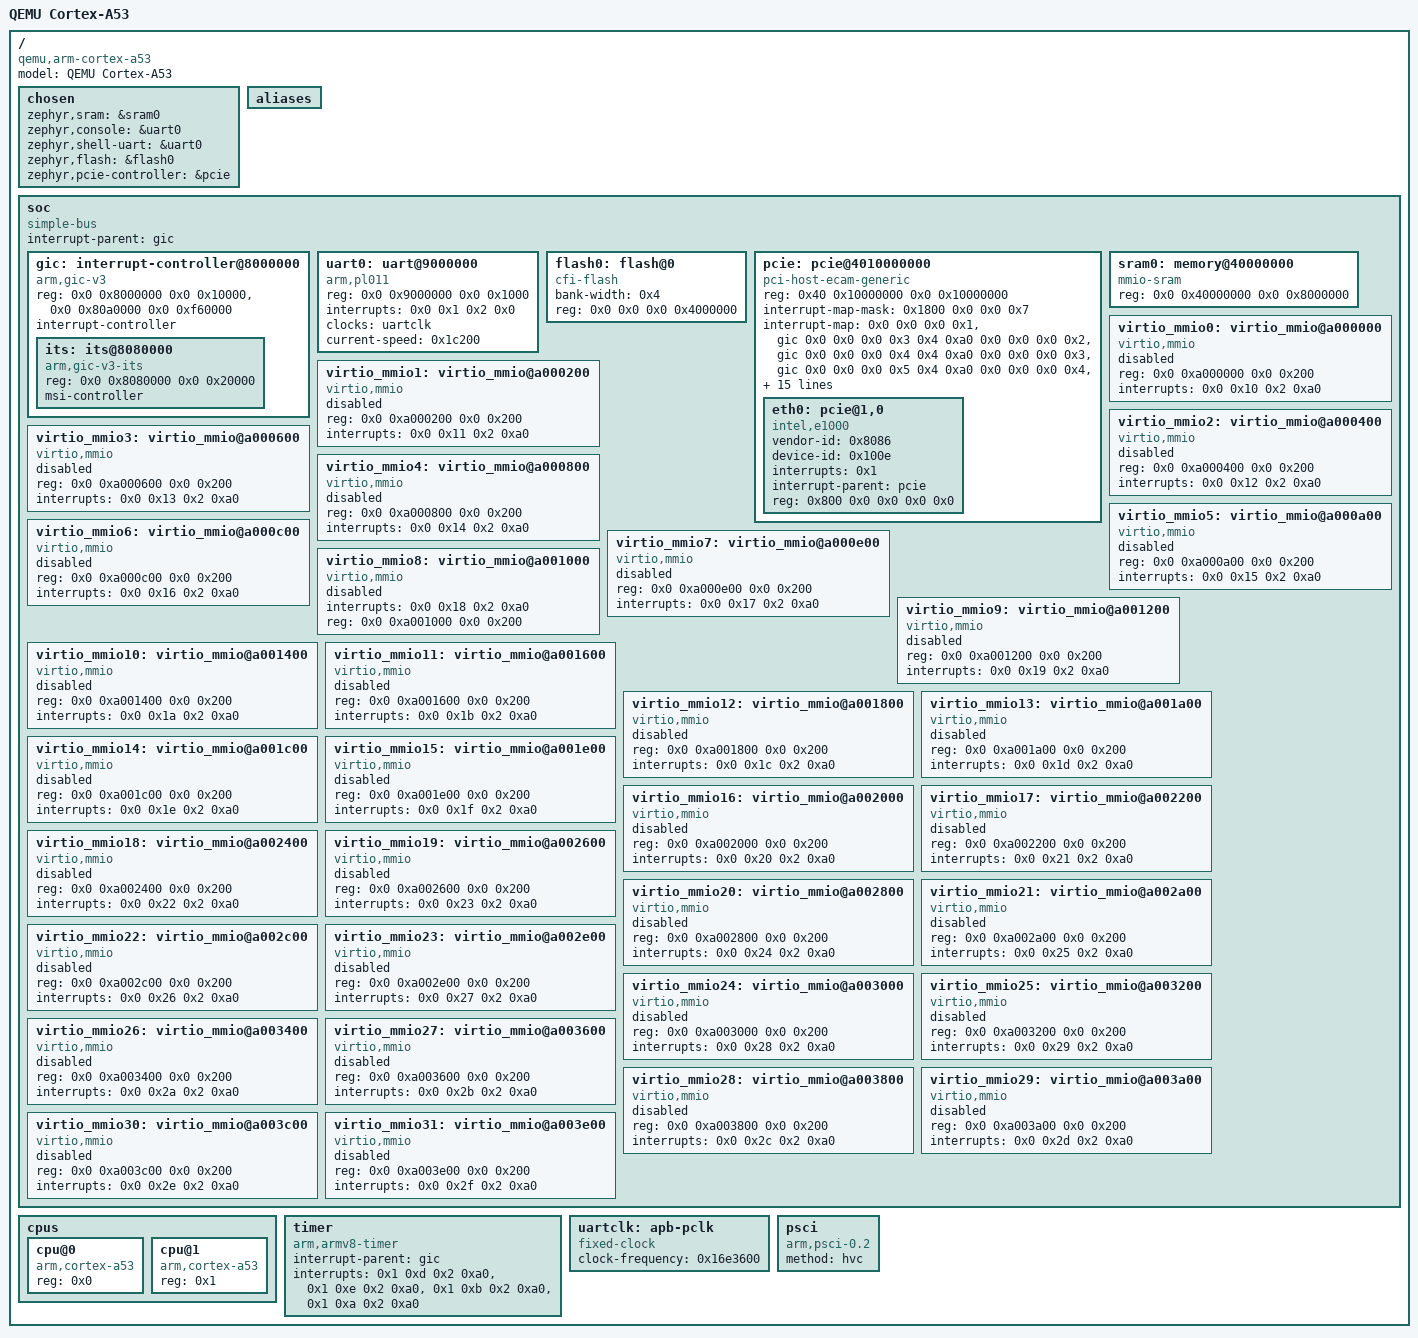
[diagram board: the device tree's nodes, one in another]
/dts-v1/;

/* node '/' defined in zephyr/dts/common/skeleton.dtsi:9 */
/ {
	#address-cells = < 0x2 >;           /* in zephyr/dts/arm64/qemu/qemu-virt-a53.dtsi:22 */
	#size-cells = < 0x2 >;              /* in zephyr/dts/arm64/qemu/qemu-virt-a53.dtsi:23 */
	model = "QEMU Cortex-A53";          /* in zephyr/boards/qemu/cortex_a53/qemu_cortex_a53.dts:12 */
	compatible = "qemu,arm-cortex-a53"; /* in zephyr/boards/qemu/cortex_a53/qemu_cortex_a53.dts:13 */

	/* node '/chosen' defined in zephyr/dts/common/skeleton.dtsi:13 */
	chosen {
		zephyr,sram = &sram0;           /* in zephyr/boards/qemu/cortex_a53/qemu_cortex_a53.dts:21 */
		zephyr,console = &uart0;        /* in zephyr/boards/qemu/cortex_a53/qemu_cortex_a53.dts:22 */
		zephyr,shell-uart = &uart0;     /* in zephyr/boards/qemu/cortex_a53/qemu_cortex_a53.dts:23 */
		zephyr,flash = &flash0;         /* in zephyr/boards/qemu/cortex_a53/qemu_cortex_a53.dts:24 */
		zephyr,pcie-controller = &pcie; /* in zephyr/boards/qemu/cortex_a53/qemu_cortex_a53.dts:25 */
	};

	/* node '/aliases' defined in zephyr/dts/common/skeleton.dtsi:15 */
	aliases {
	};

	/* node '/soc' defined in zephyr/dts/arm64/armv8-a.dtsi:10 */
	soc {
		compatible = "simple-bus";   /* in zephyr/dts/arm64/armv8-a.dtsi:13 */
		#address-cells = < 0x2 >;    /* in zephyr/dts/arm64/qemu/qemu-virt-a53.dtsi:62 */
		#size-cells = < 0x2 >;       /* in zephyr/dts/arm64/qemu/qemu-virt-a53.dtsi:63 */
		ranges;                      /* in zephyr/dts/arm64/qemu/qemu-virt-a53.dtsi:64 */
		interrupt-parent = < &gic >; /* in zephyr/dts/arm64/qemu/qemu-virt-a53.dtsi:66 */

		/* node '/soc/interrupt-controller@8000000' defined in zephyr/dts/arm64/qemu/qemu-virt-a53.dtsi:68 */
		gic: interrupt-controller@8000000 {
			compatible = "arm,gic-v3",
			             "arm,gic";               /* in zephyr/dts/arm64/qemu/qemu-virt-a53.dtsi:69 */
			reg = < 0x0 0x8000000 0x0 0x10000 >,
			      < 0x0 0x80a0000 0x0 0xf60000 >; /* in zephyr/dts/arm64/qemu/qemu-virt-a53.dtsi:70 */
			interrupt-controller;                 /* in zephyr/dts/arm64/qemu/qemu-virt-a53.dtsi:72 */
			#interrupt-cells = < 0x4 >;           /* in zephyr/dts/arm64/qemu/qemu-virt-a53.dtsi:73 */
			status = "okay";                      /* in zephyr/dts/arm64/qemu/qemu-virt-a53.dtsi:74 */
			#size-cells = < 0x2 >;                /* in zephyr/dts/arm64/qemu/qemu-virt-a53.dtsi:75 */
			#address-cells = < 0x2 >;             /* in zephyr/dts/arm64/qemu/qemu-virt-a53.dtsi:76 */
			phandle = < 0x1 >;                    /* in zephyr/dts/arm64/qemu/qemu-virt-a53.dtsi:66 */

			/* node '/soc/interrupt-controller@8000000/its@8080000' defined in zephyr/dts/arm64/qemu/qemu-virt-a53.dtsi:78 */
			its: its@8080000 {
				compatible = "arm,gic-v3-its";       /* in zephyr/dts/arm64/qemu/qemu-virt-a53.dtsi:79 */
				reg = < 0x0 0x8080000 0x0 0x20000 >; /* in zephyr/dts/arm64/qemu/qemu-virt-a53.dtsi:80 */
				msi-controller;                      /* in zephyr/dts/arm64/qemu/qemu-virt-a53.dtsi:81 */
				phandle = < 0x3 >;                   /* in zephyr/dts/arm64/qemu/qemu-virt-a53.dtsi:147 */
			};
		};

		/* node '/soc/uart@9000000' defined in zephyr/dts/arm64/qemu/qemu-virt-a53.dtsi:85 */
		uart0: uart@9000000 {
			compatible = "arm,pl011";           /* in zephyr/dts/arm64/qemu/qemu-virt-a53.dtsi:86 */
			reg = < 0x0 0x9000000 0x0 0x1000 >; /* in zephyr/dts/arm64/qemu/qemu-virt-a53.dtsi:87 */
			interrupts = < 0x0 0x1 0x2 0x0 >;   /* in zephyr/dts/arm64/qemu/qemu-virt-a53.dtsi:89 */
			interrupt-names = "irq_0";          /* in zephyr/dts/arm64/qemu/qemu-virt-a53.dtsi:90 */
			clocks = < &uartclk >;              /* in zephyr/dts/arm64/qemu/qemu-virt-a53.dtsi:91 */
			status = "okay";                    /* in zephyr/boards/qemu/cortex_a53/qemu_cortex_a53.dts:261 */
			current-speed = < 0x1c200 >;        /* in zephyr/boards/qemu/cortex_a53/qemu_cortex_a53.dts:262 */
		};

		/* node '/soc/flash@0' defined in zephyr/dts/arm64/qemu/qemu-virt-a53.dtsi:94 */
		flash0: flash@0 {
			compatible = "cfi-flash";        /* in zephyr/dts/arm64/qemu/qemu-virt-a53.dtsi:95 */
			bank-width = < 0x4 >;            /* in zephyr/dts/arm64/qemu/qemu-virt-a53.dtsi:96 */
			reg = < 0x0 0x0 0x0 0x4000000 >; /* in zephyr/dts/arm64/qemu/qemu-virt-a53.dtsi:101 */
		};

		/* node '/soc/pcie@4010000000' defined in zephyr/dts/arm64/qemu/qemu-virt-a53.dtsi:104 */
		pcie: pcie@4010000000 {
			compatible = "pci-host-ecam-generic";                                                                 /* in zephyr/dts/arm64/qemu/qemu-virt-a53.dtsi:105 */
			device_type = "pci";                                                                                  /* in zephyr/dts/arm64/qemu/qemu-virt-a53.dtsi:106 */
			reg = < 0x40 0x10000000 0x0 0x10000000 >;                                                             /* in zephyr/dts/arm64/qemu/qemu-virt-a53.dtsi:107 */
			#size-cells = < 0x2 >;                                                                                /* in zephyr/dts/arm64/qemu/qemu-virt-a53.dtsi:108 */
			#address-cells = < 0x3 >;                                                                             /* in zephyr/dts/arm64/qemu/qemu-virt-a53.dtsi:109 */
			ranges = < 0x1000000 0x0 0x0 0x0 0x3eff0000 0x0 0x10000 0x2000000 0x0 0x10000000 0x0 0x10000000
			           0x0 0x2eff0000 0x3000000 0x80 0x0 0x80 0x0 0x80 0x0 >;                                     /* in zephyr/dts/arm64/qemu/qemu-virt-a53.dtsi:110 */
			#interrupt-cells = < 0x1 >;                                                                           /* in zephyr/dts/arm64/qemu/qemu-virt-a53.dtsi:113 */
			interrupt-map-mask = < 0x1800 0x0 0x0 0x7 >;                                                          /* in zephyr/dts/arm64/qemu/qemu-virt-a53.dtsi:114 */
			interrupt-map = < 0x0 0x0 0x0 0x1 &gic 0x0 0x0 0x0 0x3 0x4 0xa0 0x0 0x0 0x0 0x2 &gic 0x0 0x0 0x0 0x4
			                  0x4 0xa0 0x0 0x0 0x0 0x3 &gic 0x0 0x0 0x0 0x5 0x4 0xa0 0x0 0x0 0x0 0x4 &gic 0x0 0x0
			                  0x0 0x6 0x4 0xa0 0x800 0x0 0x0 0x1 &gic 0x0 0x0 0x0 0x4 0x4 0xa0 0x800 0x0 0x0 0x2
			                  &gic 0x0 0x0 0x0 0x5 0x4 0xa0 0x800 0x0 0x0 0x3 &gic 0x0 0x0 0x0 0x6 0x4 0xa0 0x800
			                  0x0 0x0 0x4 &gic 0x0 0x0 0x0 0x3 0x4 0xa0 0x1000 0x0 0x0 0x1 &gic 0x0 0x0 0x0 0x5
			                  0x4 0xa0 0x1000 0x0 0x0 0x2 &gic 0x0 0x0 0x0 0x6 0x4 0xa0 0x1000 0x0 0x0 0x3 &gic
			                  0x0 0x0 0x0 0x3 0x4 0xa0 0x1000 0x0 0x0 0x4 &gic 0x0 0x0 0x0 0x4 0x4 0xa0 0x1800
			                  0x0 0x0 0x1 &gic 0x0 0x0 0x0 0x6 0x4 0xa0 0x1800 0x0 0x0 0x2 &gic 0x0 0x0 0x0 0x3
			                  0x4 0xa0 0x1800 0x0 0x0 0x3 &gic 0x0 0x0 0x0 0x4 0x4 0xa0 0x1800 0x0 0x0 0x4 &gic
			                  0x0 0x0 0x0 0x5 0x4 0xa0 >;                                                         /* in zephyr/dts/arm64/qemu/qemu-virt-a53.dtsi:115 */
			msi-parent = < &its >;                                                                                /* in zephyr/dts/arm64/qemu/qemu-virt-a53.dtsi:147 */
			bus-range = < 0x0 0xff >;                                                                             /* in zephyr/dts/arm64/qemu/qemu-virt-a53.dtsi:148 */
			phandle = < 0x4 >;                                                                                    /* in zephyr/boards/qemu/cortex_a53/qemu_cortex_a53.dts:271 */

			/* node '/soc/pcie@4010000000/pcie@1,0' defined in zephyr/boards/qemu/cortex_a53/qemu_cortex_a53.dts:266 */
			eth0: pcie@1,0 {
				compatible = "intel,e1000";      /* in zephyr/boards/qemu/cortex_a53/qemu_cortex_a53.dts:267 */
				vendor-id = < 0x8086 >;          /* in zephyr/boards/qemu/cortex_a53/qemu_cortex_a53.dts:268 */
				device-id = < 0x100e >;          /* in zephyr/boards/qemu/cortex_a53/qemu_cortex_a53.dts:269 */
				interrupts = < 0x1 >;            /* in zephyr/boards/qemu/cortex_a53/qemu_cortex_a53.dts:270 */
				interrupt-parent = < &pcie >;    /* in zephyr/boards/qemu/cortex_a53/qemu_cortex_a53.dts:271 */
				reg = < 0x800 0x0 0x0 0x0 0x0 >; /* in zephyr/boards/qemu/cortex_a53/qemu_cortex_a53.dts:272 */
				status = "okay";                 /* in zephyr/boards/qemu/cortex_a53/qemu_cortex_a53.dts:273 */
			};
		};

		/* node '/soc/memory@40000000' defined in zephyr/boards/qemu/cortex_a53/qemu_cortex_a53.dts:29 */
		sram0: memory@40000000 {
			compatible = "mmio-sram";               /* in zephyr/boards/qemu/cortex_a53/qemu_cortex_a53.dts:30 */
			reg = < 0x0 0x40000000 0x0 0x8000000 >; /* in zephyr/boards/qemu/cortex_a53/qemu_cortex_a53.dts:31 */
		};

		/* node '/soc/virtio_mmio@a000000' defined in zephyr/boards/qemu/cortex_a53/qemu_cortex_a53.dts:34 */
		virtio_mmio0: virtio_mmio@a000000 {
			compatible = "virtio,mmio";         /* in zephyr/boards/qemu/cortex_a53/qemu_cortex_a53.dts:35 */
			reg = < 0x0 0xa000000 0x0 0x200 >;  /* in zephyr/boards/qemu/cortex_a53/qemu_cortex_a53.dts:36 */
			interrupts = < 0x0 0x10 0x2 0xa0 >; /* in zephyr/boards/qemu/cortex_a53/qemu_cortex_a53.dts:37 */
			status = "disabled";                /* in zephyr/boards/qemu/cortex_a53/qemu_cortex_a53.dts:38 */
		};

		/* node '/soc/virtio_mmio@a000200' defined in zephyr/boards/qemu/cortex_a53/qemu_cortex_a53.dts:41 */
		virtio_mmio1: virtio_mmio@a000200 {
			compatible = "virtio,mmio";         /* in zephyr/boards/qemu/cortex_a53/qemu_cortex_a53.dts:42 */
			reg = < 0x0 0xa000200 0x0 0x200 >;  /* in zephyr/boards/qemu/cortex_a53/qemu_cortex_a53.dts:43 */
			interrupts = < 0x0 0x11 0x2 0xa0 >; /* in zephyr/boards/qemu/cortex_a53/qemu_cortex_a53.dts:44 */
			status = "disabled";                /* in zephyr/boards/qemu/cortex_a53/qemu_cortex_a53.dts:45 */
		};

		/* node '/soc/virtio_mmio@a000400' defined in zephyr/boards/qemu/cortex_a53/qemu_cortex_a53.dts:48 */
		virtio_mmio2: virtio_mmio@a000400 {
			compatible = "virtio,mmio";         /* in zephyr/boards/qemu/cortex_a53/qemu_cortex_a53.dts:49 */
			reg = < 0x0 0xa000400 0x0 0x200 >;  /* in zephyr/boards/qemu/cortex_a53/qemu_cortex_a53.dts:50 */
			interrupts = < 0x0 0x12 0x2 0xa0 >; /* in zephyr/boards/qemu/cortex_a53/qemu_cortex_a53.dts:51 */
			status = "disabled";                /* in zephyr/boards/qemu/cortex_a53/qemu_cortex_a53.dts:52 */
		};

		/* node '/soc/virtio_mmio@a000600' defined in zephyr/boards/qemu/cortex_a53/qemu_cortex_a53.dts:55 */
		virtio_mmio3: virtio_mmio@a000600 {
			compatible = "virtio,mmio";         /* in zephyr/boards/qemu/cortex_a53/qemu_cortex_a53.dts:56 */
			reg = < 0x0 0xa000600 0x0 0x200 >;  /* in zephyr/boards/qemu/cortex_a53/qemu_cortex_a53.dts:57 */
			interrupts = < 0x0 0x13 0x2 0xa0 >; /* in zephyr/boards/qemu/cortex_a53/qemu_cortex_a53.dts:58 */
			status = "disabled";                /* in zephyr/boards/qemu/cortex_a53/qemu_cortex_a53.dts:59 */
		};

		/* node '/soc/virtio_mmio@a000800' defined in zephyr/boards/qemu/cortex_a53/qemu_cortex_a53.dts:62 */
		virtio_mmio4: virtio_mmio@a000800 {
			compatible = "virtio,mmio";         /* in zephyr/boards/qemu/cortex_a53/qemu_cortex_a53.dts:63 */
			reg = < 0x0 0xa000800 0x0 0x200 >;  /* in zephyr/boards/qemu/cortex_a53/qemu_cortex_a53.dts:64 */
			interrupts = < 0x0 0x14 0x2 0xa0 >; /* in zephyr/boards/qemu/cortex_a53/qemu_cortex_a53.dts:65 */
			status = "disabled";                /* in zephyr/boards/qemu/cortex_a53/qemu_cortex_a53.dts:66 */
		};

		/* node '/soc/virtio_mmio@a000a00' defined in zephyr/boards/qemu/cortex_a53/qemu_cortex_a53.dts:69 */
		virtio_mmio5: virtio_mmio@a000a00 {
			compatible = "virtio,mmio";         /* in zephyr/boards/qemu/cortex_a53/qemu_cortex_a53.dts:70 */
			reg = < 0x0 0xa000a00 0x0 0x200 >;  /* in zephyr/boards/qemu/cortex_a53/qemu_cortex_a53.dts:71 */
			interrupts = < 0x0 0x15 0x2 0xa0 >; /* in zephyr/boards/qemu/cortex_a53/qemu_cortex_a53.dts:72 */
			status = "disabled";                /* in zephyr/boards/qemu/cortex_a53/qemu_cortex_a53.dts:73 */
		};

		/* node '/soc/virtio_mmio@a000c00' defined in zephyr/boards/qemu/cortex_a53/qemu_cortex_a53.dts:76 */
		virtio_mmio6: virtio_mmio@a000c00 {
			compatible = "virtio,mmio";         /* in zephyr/boards/qemu/cortex_a53/qemu_cortex_a53.dts:77 */
			reg = < 0x0 0xa000c00 0x0 0x200 >;  /* in zephyr/boards/qemu/cortex_a53/qemu_cortex_a53.dts:78 */
			interrupts = < 0x0 0x16 0x2 0xa0 >; /* in zephyr/boards/qemu/cortex_a53/qemu_cortex_a53.dts:79 */
			status = "disabled";                /* in zephyr/boards/qemu/cortex_a53/qemu_cortex_a53.dts:80 */
		};

		/* node '/soc/virtio_mmio@a000e00' defined in zephyr/boards/qemu/cortex_a53/qemu_cortex_a53.dts:83 */
		virtio_mmio7: virtio_mmio@a000e00 {
			compatible = "virtio,mmio";         /* in zephyr/boards/qemu/cortex_a53/qemu_cortex_a53.dts:84 */
			reg = < 0x0 0xa000e00 0x0 0x200 >;  /* in zephyr/boards/qemu/cortex_a53/qemu_cortex_a53.dts:85 */
			interrupts = < 0x0 0x17 0x2 0xa0 >; /* in zephyr/boards/qemu/cortex_a53/qemu_cortex_a53.dts:86 */
			status = "disabled";                /* in zephyr/boards/qemu/cortex_a53/qemu_cortex_a53.dts:87 */
		};

		/* node '/soc/virtio_mmio@a001000' defined in zephyr/boards/qemu/cortex_a53/qemu_cortex_a53.dts:90 */
		virtio_mmio8: virtio_mmio@a001000 {
			compatible = "virtio,mmio";         /* in zephyr/boards/qemu/cortex_a53/qemu_cortex_a53.dts:91 */
			interrupts = < 0x0 0x18 0x2 0xa0 >; /* in zephyr/boards/qemu/cortex_a53/qemu_cortex_a53.dts:92 */
			reg = < 0x0 0xa001000 0x0 0x200 >;  /* in zephyr/boards/qemu/cortex_a53/qemu_cortex_a53.dts:93 */
			status = "disabled";                /* in zephyr/boards/qemu/cortex_a53/qemu_cortex_a53.dts:94 */
		};

		/* node '/soc/virtio_mmio@a001200' defined in zephyr/boards/qemu/cortex_a53/qemu_cortex_a53.dts:97 */
		virtio_mmio9: virtio_mmio@a001200 {
			compatible = "virtio,mmio";         /* in zephyr/boards/qemu/cortex_a53/qemu_cortex_a53.dts:98 */
			reg = < 0x0 0xa001200 0x0 0x200 >;  /* in zephyr/boards/qemu/cortex_a53/qemu_cortex_a53.dts:99 */
			interrupts = < 0x0 0x19 0x2 0xa0 >; /* in zephyr/boards/qemu/cortex_a53/qemu_cortex_a53.dts:100 */
			status = "disabled";                /* in zephyr/boards/qemu/cortex_a53/qemu_cortex_a53.dts:101 */
		};

		/* node '/soc/virtio_mmio@a001400' defined in zephyr/boards/qemu/cortex_a53/qemu_cortex_a53.dts:104 */
		virtio_mmio10: virtio_mmio@a001400 {
			compatible = "virtio,mmio";         /* in zephyr/boards/qemu/cortex_a53/qemu_cortex_a53.dts:105 */
			reg = < 0x0 0xa001400 0x0 0x200 >;  /* in zephyr/boards/qemu/cortex_a53/qemu_cortex_a53.dts:106 */
			interrupts = < 0x0 0x1a 0x2 0xa0 >; /* in zephyr/boards/qemu/cortex_a53/qemu_cortex_a53.dts:107 */
			status = "disabled";                /* in zephyr/boards/qemu/cortex_a53/qemu_cortex_a53.dts:108 */
		};

		/* node '/soc/virtio_mmio@a001600' defined in zephyr/boards/qemu/cortex_a53/qemu_cortex_a53.dts:111 */
		virtio_mmio11: virtio_mmio@a001600 {
			compatible = "virtio,mmio";         /* in zephyr/boards/qemu/cortex_a53/qemu_cortex_a53.dts:112 */
			reg = < 0x0 0xa001600 0x0 0x200 >;  /* in zephyr/boards/qemu/cortex_a53/qemu_cortex_a53.dts:113 */
			interrupts = < 0x0 0x1b 0x2 0xa0 >; /* in zephyr/boards/qemu/cortex_a53/qemu_cortex_a53.dts:114 */
			status = "disabled";                /* in zephyr/boards/qemu/cortex_a53/qemu_cortex_a53.dts:115 */
		};

		/* node '/soc/virtio_mmio@a001800' defined in zephyr/boards/qemu/cortex_a53/qemu_cortex_a53.dts:118 */
		virtio_mmio12: virtio_mmio@a001800 {
			compatible = "virtio,mmio";         /* in zephyr/boards/qemu/cortex_a53/qemu_cortex_a53.dts:119 */
			reg = < 0x0 0xa001800 0x0 0x200 >;  /* in zephyr/boards/qemu/cortex_a53/qemu_cortex_a53.dts:120 */
			interrupts = < 0x0 0x1c 0x2 0xa0 >; /* in zephyr/boards/qemu/cortex_a53/qemu_cortex_a53.dts:121 */
			status = "disabled";                /* in zephyr/boards/qemu/cortex_a53/qemu_cortex_a53.dts:122 */
		};

		/* node '/soc/virtio_mmio@a001a00' defined in zephyr/boards/qemu/cortex_a53/qemu_cortex_a53.dts:125 */
		virtio_mmio13: virtio_mmio@a001a00 {
			compatible = "virtio,mmio";         /* in zephyr/boards/qemu/cortex_a53/qemu_cortex_a53.dts:126 */
			reg = < 0x0 0xa001a00 0x0 0x200 >;  /* in zephyr/boards/qemu/cortex_a53/qemu_cortex_a53.dts:127 */
			interrupts = < 0x0 0x1d 0x2 0xa0 >; /* in zephyr/boards/qemu/cortex_a53/qemu_cortex_a53.dts:128 */
			status = "disabled";                /* in zephyr/boards/qemu/cortex_a53/qemu_cortex_a53.dts:129 */
		};

		/* node '/soc/virtio_mmio@a001c00' defined in zephyr/boards/qemu/cortex_a53/qemu_cortex_a53.dts:132 */
		virtio_mmio14: virtio_mmio@a001c00 {
			compatible = "virtio,mmio";         /* in zephyr/boards/qemu/cortex_a53/qemu_cortex_a53.dts:133 */
			reg = < 0x0 0xa001c00 0x0 0x200 >;  /* in zephyr/boards/qemu/cortex_a53/qemu_cortex_a53.dts:134 */
			interrupts = < 0x0 0x1e 0x2 0xa0 >; /* in zephyr/boards/qemu/cortex_a53/qemu_cortex_a53.dts:135 */
			status = "disabled";                /* in zephyr/boards/qemu/cortex_a53/qemu_cortex_a53.dts:136 */
		};

		/* node '/soc/virtio_mmio@a001e00' defined in zephyr/boards/qemu/cortex_a53/qemu_cortex_a53.dts:139 */
		virtio_mmio15: virtio_mmio@a001e00 {
			compatible = "virtio,mmio";         /* in zephyr/boards/qemu/cortex_a53/qemu_cortex_a53.dts:140 */
			reg = < 0x0 0xa001e00 0x0 0x200 >;  /* in zephyr/boards/qemu/cortex_a53/qemu_cortex_a53.dts:141 */
			interrupts = < 0x0 0x1f 0x2 0xa0 >; /* in zephyr/boards/qemu/cortex_a53/qemu_cortex_a53.dts:142 */
			status = "disabled";                /* in zephyr/boards/qemu/cortex_a53/qemu_cortex_a53.dts:143 */
		};

		/* node '/soc/virtio_mmio@a002000' defined in zephyr/boards/qemu/cortex_a53/qemu_cortex_a53.dts:146 */
		virtio_mmio16: virtio_mmio@a002000 {
			compatible = "virtio,mmio";         /* in zephyr/boards/qemu/cortex_a53/qemu_cortex_a53.dts:147 */
			reg = < 0x0 0xa002000 0x0 0x200 >;  /* in zephyr/boards/qemu/cortex_a53/qemu_cortex_a53.dts:148 */
			interrupts = < 0x0 0x20 0x2 0xa0 >; /* in zephyr/boards/qemu/cortex_a53/qemu_cortex_a53.dts:149 */
			status = "disabled";                /* in zephyr/boards/qemu/cortex_a53/qemu_cortex_a53.dts:150 */
		};

		/* node '/soc/virtio_mmio@a002200' defined in zephyr/boards/qemu/cortex_a53/qemu_cortex_a53.dts:153 */
		virtio_mmio17: virtio_mmio@a002200 {
			compatible = "virtio,mmio";         /* in zephyr/boards/qemu/cortex_a53/qemu_cortex_a53.dts:154 */
			reg = < 0x0 0xa002200 0x0 0x200 >;  /* in zephyr/boards/qemu/cortex_a53/qemu_cortex_a53.dts:155 */
			interrupts = < 0x0 0x21 0x2 0xa0 >; /* in zephyr/boards/qemu/cortex_a53/qemu_cortex_a53.dts:156 */
			status = "disabled";                /* in zephyr/boards/qemu/cortex_a53/qemu_cortex_a53.dts:157 */
		};

		/* node '/soc/virtio_mmio@a002400' defined in zephyr/boards/qemu/cortex_a53/qemu_cortex_a53.dts:160 */
		virtio_mmio18: virtio_mmio@a002400 {
			compatible = "virtio,mmio";         /* in zephyr/boards/qemu/cortex_a53/qemu_cortex_a53.dts:161 */
			reg = < 0x0 0xa002400 0x0 0x200 >;  /* in zephyr/boards/qemu/cortex_a53/qemu_cortex_a53.dts:162 */
			interrupts = < 0x0 0x22 0x2 0xa0 >; /* in zephyr/boards/qemu/cortex_a53/qemu_cortex_a53.dts:163 */
			status = "disabled";                /* in zephyr/boards/qemu/cortex_a53/qemu_cortex_a53.dts:164 */
		};

		/* node '/soc/virtio_mmio@a002600' defined in zephyr/boards/qemu/cortex_a53/qemu_cortex_a53.dts:167 */
		virtio_mmio19: virtio_mmio@a002600 {
			compatible = "virtio,mmio";         /* in zephyr/boards/qemu/cortex_a53/qemu_cortex_a53.dts:168 */
			reg = < 0x0 0xa002600 0x0 0x200 >;  /* in zephyr/boards/qemu/cortex_a53/qemu_cortex_a53.dts:169 */
			interrupts = < 0x0 0x23 0x2 0xa0 >; /* in zephyr/boards/qemu/cortex_a53/qemu_cortex_a53.dts:170 */
			status = "disabled";                /* in zephyr/boards/qemu/cortex_a53/qemu_cortex_a53.dts:171 */
		};

		/* node '/soc/virtio_mmio@a002800' defined in zephyr/boards/qemu/cortex_a53/qemu_cortex_a53.dts:174 */
		virtio_mmio20: virtio_mmio@a002800 {
			compatible = "virtio,mmio";         /* in zephyr/boards/qemu/cortex_a53/qemu_cortex_a53.dts:175 */
			reg = < 0x0 0xa002800 0x0 0x200 >;  /* in zephyr/boards/qemu/cortex_a53/qemu_cortex_a53.dts:176 */
			interrupts = < 0x0 0x24 0x2 0xa0 >; /* in zephyr/boards/qemu/cortex_a53/qemu_cortex_a53.dts:177 */
			status = "disabled";                /* in zephyr/boards/qemu/cortex_a53/qemu_cortex_a53.dts:178 */
		};

		/* node '/soc/virtio_mmio@a002a00' defined in zephyr/boards/qemu/cortex_a53/qemu_cortex_a53.dts:181 */
		virtio_mmio21: virtio_mmio@a002a00 {
			compatible = "virtio,mmio";         /* in zephyr/boards/qemu/cortex_a53/qemu_cortex_a53.dts:182 */
			reg = < 0x0 0xa002a00 0x0 0x200 >;  /* in zephyr/boards/qemu/cortex_a53/qemu_cortex_a53.dts:183 */
			interrupts = < 0x0 0x25 0x2 0xa0 >; /* in zephyr/boards/qemu/cortex_a53/qemu_cortex_a53.dts:184 */
			status = "disabled";                /* in zephyr/boards/qemu/cortex_a53/qemu_cortex_a53.dts:185 */
		};

		/* node '/soc/virtio_mmio@a002c00' defined in zephyr/boards/qemu/cortex_a53/qemu_cortex_a53.dts:188 */
		virtio_mmio22: virtio_mmio@a002c00 {
			compatible = "virtio,mmio";         /* in zephyr/boards/qemu/cortex_a53/qemu_cortex_a53.dts:189 */
			reg = < 0x0 0xa002c00 0x0 0x200 >;  /* in zephyr/boards/qemu/cortex_a53/qemu_cortex_a53.dts:190 */
			interrupts = < 0x0 0x26 0x2 0xa0 >; /* in zephyr/boards/qemu/cortex_a53/qemu_cortex_a53.dts:191 */
			status = "disabled";                /* in zephyr/boards/qemu/cortex_a53/qemu_cortex_a53.dts:192 */
		};

		/* node '/soc/virtio_mmio@a002e00' defined in zephyr/boards/qemu/cortex_a53/qemu_cortex_a53.dts:195 */
		virtio_mmio23: virtio_mmio@a002e00 {
			compatible = "virtio,mmio";         /* in zephyr/boards/qemu/cortex_a53/qemu_cortex_a53.dts:196 */
			reg = < 0x0 0xa002e00 0x0 0x200 >;  /* in zephyr/boards/qemu/cortex_a53/qemu_cortex_a53.dts:197 */
			interrupts = < 0x0 0x27 0x2 0xa0 >; /* in zephyr/boards/qemu/cortex_a53/qemu_cortex_a53.dts:198 */
			status = "disabled";                /* in zephyr/boards/qemu/cortex_a53/qemu_cortex_a53.dts:199 */
		};

		/* node '/soc/virtio_mmio@a003000' defined in zephyr/boards/qemu/cortex_a53/qemu_cortex_a53.dts:202 */
		virtio_mmio24: virtio_mmio@a003000 {
			compatible = "virtio,mmio";         /* in zephyr/boards/qemu/cortex_a53/qemu_cortex_a53.dts:203 */
			reg = < 0x0 0xa003000 0x0 0x200 >;  /* in zephyr/boards/qemu/cortex_a53/qemu_cortex_a53.dts:204 */
			interrupts = < 0x0 0x28 0x2 0xa0 >; /* in zephyr/boards/qemu/cortex_a53/qemu_cortex_a53.dts:205 */
			status = "disabled";                /* in zephyr/boards/qemu/cortex_a53/qemu_cortex_a53.dts:206 */
		};

		/* node '/soc/virtio_mmio@a003200' defined in zephyr/boards/qemu/cortex_a53/qemu_cortex_a53.dts:209 */
		virtio_mmio25: virtio_mmio@a003200 {
			compatible = "virtio,mmio";         /* in zephyr/boards/qemu/cortex_a53/qemu_cortex_a53.dts:210 */
			reg = < 0x0 0xa003200 0x0 0x200 >;  /* in zephyr/boards/qemu/cortex_a53/qemu_cortex_a53.dts:211 */
			interrupts = < 0x0 0x29 0x2 0xa0 >; /* in zephyr/boards/qemu/cortex_a53/qemu_cortex_a53.dts:212 */
			status = "disabled";                /* in zephyr/boards/qemu/cortex_a53/qemu_cortex_a53.dts:213 */
		};

		/* node '/soc/virtio_mmio@a003400' defined in zephyr/boards/qemu/cortex_a53/qemu_cortex_a53.dts:216 */
		virtio_mmio26: virtio_mmio@a003400 {
			compatible = "virtio,mmio";         /* in zephyr/boards/qemu/cortex_a53/qemu_cortex_a53.dts:217 */
			reg = < 0x0 0xa003400 0x0 0x200 >;  /* in zephyr/boards/qemu/cortex_a53/qemu_cortex_a53.dts:218 */
			interrupts = < 0x0 0x2a 0x2 0xa0 >; /* in zephyr/boards/qemu/cortex_a53/qemu_cortex_a53.dts:219 */
			status = "disabled";                /* in zephyr/boards/qemu/cortex_a53/qemu_cortex_a53.dts:220 */
		};

		/* node '/soc/virtio_mmio@a003600' defined in zephyr/boards/qemu/cortex_a53/qemu_cortex_a53.dts:223 */
		virtio_mmio27: virtio_mmio@a003600 {
			compatible = "virtio,mmio";         /* in zephyr/boards/qemu/cortex_a53/qemu_cortex_a53.dts:224 */
			reg = < 0x0 0xa003600 0x0 0x200 >;  /* in zephyr/boards/qemu/cortex_a53/qemu_cortex_a53.dts:225 */
			interrupts = < 0x0 0x2b 0x2 0xa0 >; /* in zephyr/boards/qemu/cortex_a53/qemu_cortex_a53.dts:226 */
			status = "disabled";                /* in zephyr/boards/qemu/cortex_a53/qemu_cortex_a53.dts:227 */
		};

		/* node '/soc/virtio_mmio@a003800' defined in zephyr/boards/qemu/cortex_a53/qemu_cortex_a53.dts:230 */
		virtio_mmio28: virtio_mmio@a003800 {
			compatible = "virtio,mmio";         /* in zephyr/boards/qemu/cortex_a53/qemu_cortex_a53.dts:231 */
			reg = < 0x0 0xa003800 0x0 0x200 >;  /* in zephyr/boards/qemu/cortex_a53/qemu_cortex_a53.dts:232 */
			interrupts = < 0x0 0x2c 0x2 0xa0 >; /* in zephyr/boards/qemu/cortex_a53/qemu_cortex_a53.dts:233 */
			status = "disabled";                /* in zephyr/boards/qemu/cortex_a53/qemu_cortex_a53.dts:234 */
		};

		/* node '/soc/virtio_mmio@a003a00' defined in zephyr/boards/qemu/cortex_a53/qemu_cortex_a53.dts:237 */
		virtio_mmio29: virtio_mmio@a003a00 {
			compatible = "virtio,mmio";         /* in zephyr/boards/qemu/cortex_a53/qemu_cortex_a53.dts:238 */
			reg = < 0x0 0xa003a00 0x0 0x200 >;  /* in zephyr/boards/qemu/cortex_a53/qemu_cortex_a53.dts:239 */
			interrupts = < 0x0 0x2d 0x2 0xa0 >; /* in zephyr/boards/qemu/cortex_a53/qemu_cortex_a53.dts:240 */
			status = "disabled";                /* in zephyr/boards/qemu/cortex_a53/qemu_cortex_a53.dts:241 */
		};

		/* node '/soc/virtio_mmio@a003c00' defined in zephyr/boards/qemu/cortex_a53/qemu_cortex_a53.dts:244 */
		virtio_mmio30: virtio_mmio@a003c00 {
			compatible = "virtio,mmio";         /* in zephyr/boards/qemu/cortex_a53/qemu_cortex_a53.dts:245 */
			reg = < 0x0 0xa003c00 0x0 0x200 >;  /* in zephyr/boards/qemu/cortex_a53/qemu_cortex_a53.dts:246 */
			interrupts = < 0x0 0x2e 0x2 0xa0 >; /* in zephyr/boards/qemu/cortex_a53/qemu_cortex_a53.dts:247 */
			status = "disabled";                /* in zephyr/boards/qemu/cortex_a53/qemu_cortex_a53.dts:248 */
		};

		/* node '/soc/virtio_mmio@a003e00' defined in zephyr/boards/qemu/cortex_a53/qemu_cortex_a53.dts:251 */
		virtio_mmio31: virtio_mmio@a003e00 {
			compatible = "virtio,mmio";         /* in zephyr/boards/qemu/cortex_a53/qemu_cortex_a53.dts:252 */
			reg = < 0x0 0xa003e00 0x0 0x200 >;  /* in zephyr/boards/qemu/cortex_a53/qemu_cortex_a53.dts:253 */
			interrupts = < 0x0 0x2f 0x2 0xa0 >; /* in zephyr/boards/qemu/cortex_a53/qemu_cortex_a53.dts:254 */
			status = "disabled";                /* in zephyr/boards/qemu/cortex_a53/qemu_cortex_a53.dts:255 */
		};
	};

	/* node '/cpus' defined in zephyr/dts/arm64/qemu/qemu-virt-a53.dtsi:25 */
	cpus {
		#address-cells = < 0x1 >; /* in zephyr/dts/arm64/qemu/qemu-virt-a53.dtsi:26 */
		#size-cells = < 0x0 >;    /* in zephyr/dts/arm64/qemu/qemu-virt-a53.dtsi:27 */

		/* node '/cpus/cpu@0' defined in zephyr/dts/arm64/qemu/qemu-virt-a53.dtsi:29 */
		cpu@0 {
			device_type = "cpu";           /* in zephyr/dts/arm64/qemu/qemu-virt-a53.dtsi:30 */
			compatible = "arm,cortex-a53"; /* in zephyr/dts/arm64/qemu/qemu-virt-a53.dtsi:31 */
			reg = < 0x0 >;                 /* in zephyr/dts/arm64/qemu/qemu-virt-a53.dtsi:32 */
		};

		/* node '/cpus/cpu@1' defined in zephyr/dts/arm64/qemu/qemu-virt-a53.dtsi:35 */
		cpu@1 {
			device_type = "cpu";           /* in zephyr/dts/arm64/qemu/qemu-virt-a53.dtsi:36 */
			compatible = "arm,cortex-a53"; /* in zephyr/dts/arm64/qemu/qemu-virt-a53.dtsi:37 */
			reg = < 0x1 >;                 /* in zephyr/dts/arm64/qemu/qemu-virt-a53.dtsi:38 */
		};
	};

	/* node '/timer' defined in zephyr/dts/arm64/qemu/qemu-virt-a53.dtsi:42 */
	timer {
		compatible = "arm,armv8-timer";    /* in zephyr/dts/arm64/qemu/qemu-virt-a53.dtsi:43 */
		interrupt-parent = < &gic >;       /* in zephyr/dts/arm64/qemu/qemu-virt-a53.dtsi:44 */
		interrupts = < 0x1 0xd 0x2 0xa0 >,
		             < 0x1 0xe 0x2 0xa0 >,
		             < 0x1 0xb 0x2 0xa0 >,
		             < 0x1 0xa 0x2 0xa0 >; /* in zephyr/dts/arm64/qemu/qemu-virt-a53.dtsi:45 */
	};

	/* node '/apb-pclk' defined in zephyr/dts/arm64/qemu/qemu-virt-a53.dtsi:55 */
	uartclk: apb-pclk {
		compatible = "fixed-clock";      /* in zephyr/dts/arm64/qemu/qemu-virt-a53.dtsi:56 */
		clock-frequency = < 0x16e3600 >; /* in zephyr/dts/arm64/qemu/qemu-virt-a53.dtsi:57 */
		#clock-cells = < 0x0 >;          /* in zephyr/dts/arm64/qemu/qemu-virt-a53.dtsi:58 */
		phandle = < 0x2 >;               /* in zephyr/dts/arm64/qemu/qemu-virt-a53.dtsi:91 */
	};

	/* node '/psci' defined in zephyr/boards/qemu/cortex_a53/qemu_cortex_a53.dts:15 */
	psci {
		compatible = "arm,psci-0.2"; /* in zephyr/boards/qemu/cortex_a53/qemu_cortex_a53.dts:16 */
		method = "hvc";              /* in zephyr/boards/qemu/cortex_a53/qemu_cortex_a53.dts:17 */
	};
};
